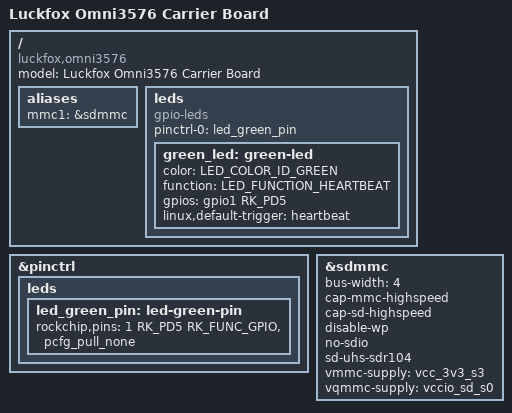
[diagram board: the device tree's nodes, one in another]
// SPDX-License-Identifier: (GPL-2.0+ OR MIT)
/*
 * Copyright (c) 2024 Rockchip Electronics Co., Ltd.
 * Copyright (c) 2025 John Clark <inindev@gmail.com>
 */

/dts-v1/;

#include "rk3576-luckfox-core3576.dtsi"

/ {
	model = "Luckfox Omni3576 Carrier Board";
	compatible = "luckfox,omni3576", "luckfox,core3576", "rockchip,rk3576";

	aliases {
		mmc1 = &sdmmc;
	};

	leds: leds {
		compatible = "gpio-leds";
		pinctrl-names = "default";
		pinctrl-0 = <&led_green_pin>;

		green_led: green-led {
			color = <LED_COLOR_ID_GREEN>;
			function = LED_FUNCTION_HEARTBEAT;
			gpios = <&gpio1 RK_PD5 GPIO_ACTIVE_HIGH>;
			linux,default-trigger = "heartbeat";
		};
	};
};

&pinctrl {
	leds {
		led_green_pin: led-green-pin {
			rockchip,pins = <1 RK_PD5 RK_FUNC_GPIO &pcfg_pull_none>;
		};
	};
};

&sdmmc {
	bus-width = <4>;
	cap-mmc-highspeed;
	cap-sd-highspeed;
	disable-wp;
	no-sdio;
	sd-uhs-sdr104;
	vmmc-supply = <&vcc_3v3_s3>;
	vqmmc-supply = <&vccio_sd_s0>;
	status = "okay";
};
